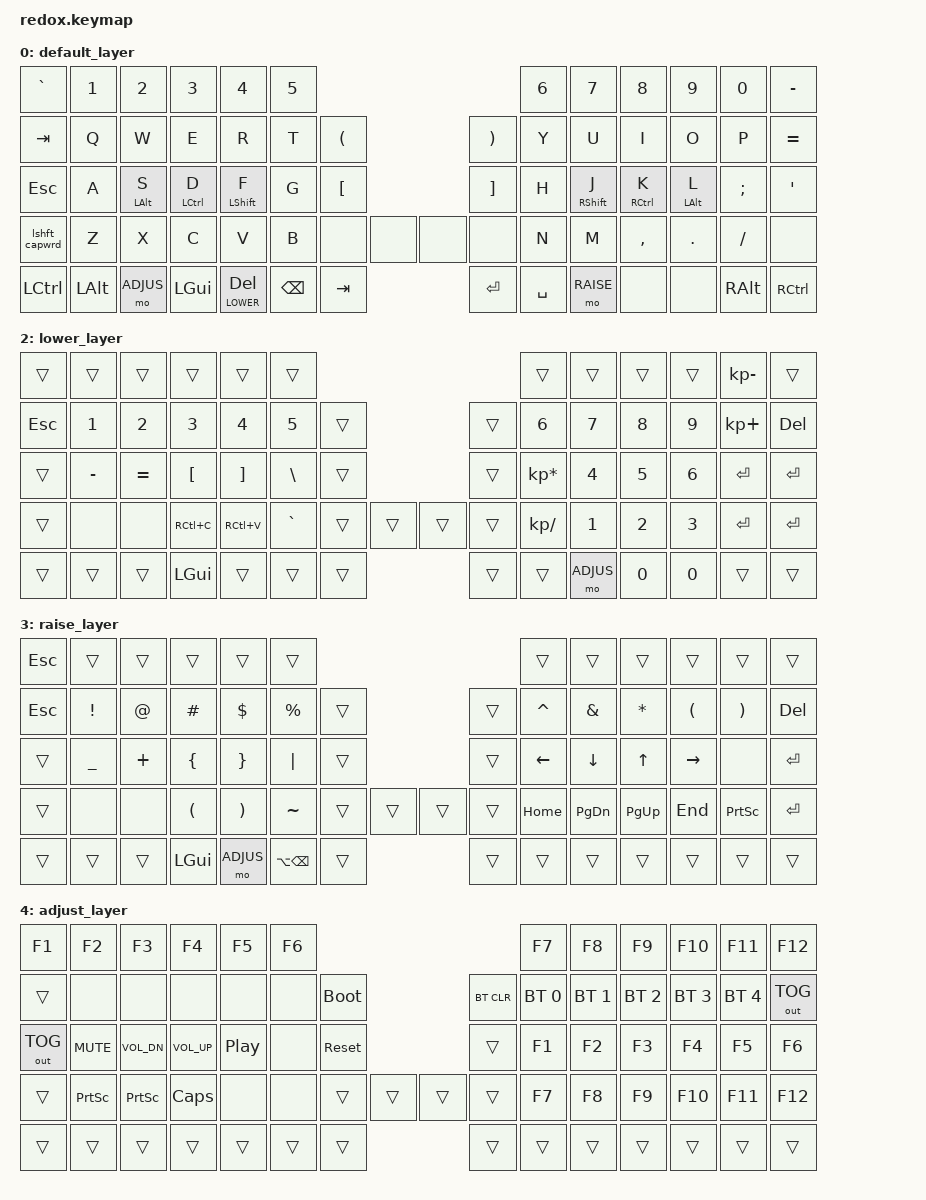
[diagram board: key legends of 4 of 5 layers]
/*
 * Copyright (c) 2021 The ZMK Contributors
 *
 * SPDX-License-Identifier: MIT
 */

#include <behaviors.dtsi>
#include <dt-bindings/zmk/keys.h>
#include <dt-bindings/zmk/bt.h>
#include <dt-bindings/zmk/ext_power.h>
#include <dt-bindings/zmk/outputs.h>

#include "zmk-helpers/key-labels/redox.h"
#include "zmk-helpers/helper.h"

#define NONE &none
#define ___ &trans

#define DEFAULT 0
#define GAME    1
#define LOWER   2
#define RAISE   3
#define ADJUS   4
#define EXTRA_1 5
#define EXTRA_2 6

/* Global settings */

#define QUICK_TAP_MS 175

&caps_word {
    continue-list = <UNDERSCORE MINUS BACKSPACE DELETE>;
};

&sk {  // sticky-key config
    release-after-ms = <900>;  // release after 0.9s
    quick-release;             // no double capitalization when rolling keys
};

&sl {  // sticky-layer config
    ignore-modifiers;          // allow chording sticky mods & layers
};

&lt {  // layer-tap config
    flavor = "balanced";
    tapping-term-ms = <200>;
    quick-tap-ms = <QUICK_TAP_MS>;
};

/* Homerow mods */

#define LN_ROW LN6 LN5 LN4 LN3 LN2 LN1
#define LT_ROW LT6 LT5 LT4 LT3 LT2 LT1 LT0
#define LM_ROW LM6 LM5 LM4 LM3 LM2 LM1 LM0
#define LB_ROW LB6 LB5 LB4 LB3 LB2 LB1
#define LF_ROW LF6 LF5 LF4 LF3
#define L_THUMB LH4 LH3 LH2 LH1 LH0

#define RN_ROW RN6 RN5 RN4 RN3 RN2 RN1
#define RT_ROW RT6 RT5 RT4 RT3 RT2 RT1 RT0
#define RM_ROW RM6 RM5 RM4 RM3 RM2 RM1 RM0
#define RB_ROW RB6 RB5 RB4 RB3 RB2 RB1
#define RF_ROW RF6 RF5 RF4 RF3
#define R_THUMB RH4 RH3 RH2 RH1 RH0

#define KEYS_L LN_ROW LT_ROW LM_ROW LB_ROW LF_ROW // left hand
#define KEYS_R RN_ROW RT_ROW RM_ROW RB_ROW RF_ROW // right hand

#define THUMBS L_THUMB R_THUMB

#define MAKE_HRM(NAME, HOLD, TAP, TRIGGER_POS) \
    ZMK_HOLD_TAP(NAME, \
        flavor = "balanced"; \
        tapping-term-ms = <200>; \
        quick-tap-ms = <QUICK_TAP_MS>; \
        require-prior-idle-ms = <150>; \
        bindings = <HOLD>, <TAP>; \
        hold-trigger-key-positions = <TRIGGER_POS>; \
        hold-trigger-on-release; \
    )
MAKE_HRM(hml, &kp, &kp, KEYS_R THUMBS)  // left-hand HRMs
MAKE_HRM(hmr, &kp, &kp, KEYS_L THUMBS)  // right-hand HRMs


ZMK_COMBO(toggle_game_layer, &tog GAME, LB2 LB1, DEFAULT GAME)


/ {
    behaviors {
        lshft_capwrd: behavior_lshift_capsword {
            compatible = "zmk,behavior-tap-dance";
            label = "LSHFT_CAPSWORD";
            #binding-cells = <0>;
            tapping-term-ms = <200>;
            bindings = <&kp LSHFT>, <&caps_word>;
        };
    };

    keymap {
        compatible =  "zmk,keymap" ;

        default_layer {
// --------------------------------------------------------------------------------------------------------------------------------
// | `     |  1  |  2  |   3   |  4  |  5  |                   ---                |  6    |  7    |  8    |  9   | 0    |     -     |
// | TAB   |  Q  |  W  |   E   |  R  |  T  |   (   |           ---        |  )    |  Y    |  U    |  I    |  O   | P    |     =     |
// | ESC   |  A  |  S  |   D   |  F  |  G  |   [   |           ---        |  ]    |  H    |  J    |  K    |  L   | ;    |     '     |
// | SHIFT |  Z  |  X  |   C   |  V  |  B  | NONE  | NONE    | --- | NONE | NONE  |  N    |  M    |  ,    |  .   | /    |   SHIFT   |
// | CRTL  | ALT |ADJUS| GUI   | LOWER/DEL | BSPC  | TAB     | --- | RET  | SPACE |     RAISE     | NONE  | NONE | RALT |   RCTRL   |
            bindings = <
// ╭───────────────┬───────────────┬───────────────┬───────────────┬───────────────┬───────────────╮                                                                  ╭───────────────┬───────────────┬───────────────┬───────────────┬───────────────┬───────────────╮
     &kp GRAVE       &kp N1          &kp N2          &kp N3          &kp N4          &kp N5                                                                             &kp N6          &kp N7          &kp N8          &kp N9          &kp N0          &kp MINUS
// ├───────────────┼───────────────┼───────────────┼───────────────┼───────────────┼───────────────┼───────────────╮                                  ╭───────────────┼───────────────┼───────────────┼───────────────┼───────────────┼───────────────┼───────────────┤
     &kp TAB         &kp Q           &kp W           &kp E           &kp R           &kp T           &kp LPAR                                           &kp RPAR        &kp Y           &kp U           &kp I           &kp O           &kp P           &kp EQUAL
// ├───────────────┼───────────────┼───────────────┼───────────────┼───────────────┼───────────────┼───────────────┤                                  ├───────────────┼───────────────┼───────────────┼───────────────┼───────────────┼───────────────┼───────────────┤
     &kp ESC         &kp A           &hml LALT S     &hml LCTRL D    &hml LSHFT F    &kp G           &kp LBKT                                           &kp RBKT        &kp H           &hmr RSHFT J    &hmr RCTRL K    &hmr LALT L     &kp SEMI        &kp SQT
// ├───────────────┼───────────────┼───────────────┼───────────────┼───────────────┼───────────────┼───────────────┼───────────────╮  ╭───────────────┼───────────────┼───────────────┼───────────────┼───────────────┼───────────────┼───────────────┼───────────────┤
     &lshft_capwrd   &kp Z           &kp X           &kp C           &kp V           &kp B           NONE            NONE               NONE            NONE            &kp N           &kp M           &kp COMMA       &kp DOT         &kp FSLH        NONE
// ├───────────────┼───────────────┼───────────────┼───────────────┼───────────────┼───────────────┼───────────────┼───────────────┤  ├───────────────┼───────────────┼───────────────┼───────────────┼───────────────┼───────────────┼───────────────┼───────────────┤
     &kp LCTRL       &kp LALT        &mo ADJUS       &kp LGUI                &lt LOWER DEL           &kp BSPC        &kp TAB            &kp RET         &kp SPACE                &mo RAISE              NONE            NONE            &kp RALT        &kp RCTRL
// ╰───────────────┴───────────────┴───────────────┴───────────────┴───────────────────────────────┴───────────────┴───────────────╯  ╰───────────────┴───────────────┴───────────────────────────────┴───────────────┴───────────────┴───────────────┴───────────────╯
            >;
        };

        game_layer {
// --------------------------------------------------------------------------------------------------------------------------------
// | `     |  1  |  2  |   3   |  4  |  5  |                   ---                |  6    |  7    |  8    |  9   | 0    |     -     |
// | TAB   |  Q  |  W  |   E   |  R  |  T  |   (   |           ---        |  )    |  Y    |  U    |  I    |  O   | P    |     =     |
// | ESC   |  A  |  S  |   D   |  F  |  G  |   [   |           ---        |  ]    |  H    |  J    |  K    |  L   | ;    |     '     |
// | SHIFT |  Z  |  X  |   C   |  V  |  B  | NONE  | NONE    | --- | NONE | NONE  |  N    |  M    |  ,    |  .   | /    |   SHIFT   |
// | CRTL  | ALT |ADJUS| GUI   | LOWER/DEL | BSPC  | TAB     | --- | RET  | SPACE |     RAISE     | NONE  | NONE | RALT |   RCTRL   |
            bindings = <
// ╭───────────────┬───────────────┬───────────────┬───────────────┬───────────────┬───────────────╮                                                                  ╭───────────────┬───────────────┬───────────────┬───────────────┬───────────────┬───────────────╮
     ___             ___             ___             ___             ___             ___                                                                                ___             ___             ___             ___             ___             ___
// ├───────────────┼───────────────┼───────────────┼───────────────┼───────────────┼───────────────┼───────────────╮                                  ╭───────────────┼───────────────┼───────────────┼───────────────┼───────────────┼───────────────┼───────────────┤
     ___             ___             ___             ___             ___             ___             ___                                                ___             ___             ___             ___             ___             ___             ___
// ├───────────────┼───────────────┼───────────────┼───────────────┼───────────────┼───────────────┼───────────────┤                                  ├───────────────┼───────────────┼───────────────┼───────────────┼───────────────┼───────────────┼───────────────┤
     ___             &kp A           &kp S           &kp D           &kp F           ___             ___                                                ___             ___             &kp J           &kp K           &kp L           &kp SEMI        ___
// ├───────────────┼───────────────┼───────────────┼───────────────┼───────────────┼───────────────┼───────────────┼───────────────╮  ╭───────────────┼───────────────┼───────────────┼───────────────┼───────────────┼───────────────┼───────────────┼───────────────┤
     ___             ___             ___             ___             ___             ___             ___             ___                ___             ___             ___             ___             ___             ___             ___             ___
// ├───────────────┼───────────────┼───────────────┼───────────────┼───────────────┼───────────────┼───────────────┼───────────────┤  ├───────────────┼───────────────┼───────────────┼───────────────┼───────────────┼───────────────┼───────────────┼───────────────┤
     ___             ___             ___             ___             ___             ___             ___             ___                ___             ___             ___             ___             ___             ___             ___             ___
// ╰───────────────┴───────────────┴───────────────┴───────────────┴───────────────────────────────┴───────────────┴───────────────╯  ╰───────────────┴───────────────┴───────────────────────────────┴───────────────┴───────────────┴───────────────┴───────────────╯
            >;
        };

        lower_layer {
// -------------------------------------------------------------------------------------------------------------------------------------
// | `     |  1  |  2  |   3   |   4   |  5    |                       ---                   |  6  |  7  |  8   |  9   |  -    |  -     |
// | ESC   |  1  |  2  |   3   |   4   |  5    |   (     |             ---           |  )    |  6  |  7  |  8   |  9   |  +    |  DEL   |
// | ESC   |  -  |  =  |   [   |   ]   |  \    |   [     |             ---           |  ]    |  *  |  4  |  5   |  6   |  RET  |  RET   |
// | SHIFT | NONE| NONE| COPY  | PASTE | GRAVE | DEL     | LALT    |   ---   | HOME  | END   |  \  |  1  |  2   |  3   |  RET  |  RET   |
// | CRTL  | ALT |ADJUS| GUI   |     LOWER     | BSPC    | LCTRL   |   ---   | RET   | SPACE |   RAISE   |  0   |  0   |  RALT |  RCTRL |
            bindings = <
// ╭───────────────┬───────────────┬───────────────┬───────────────┬───────────────┬───────────────╮                                                                  ╭───────────────┬───────────────┬───────────────┬───────────────┬───────────────┬───────────────╮
      ___             ___             ___             ___             ___             ___                                                                                ___             ___             ___             ___            &kp KP_MINUS     ___
// ├───────────────┼───────────────┼───────────────┼───────────────┼───────────────┼───────────────┼───────────────╮                                  ╭───────────────┼───────────────┼───────────────┼───────────────┼───────────────┼───────────────┼───────────────┤
     &kp ESC         &kp N1          &kp N2          &kp N3          &kp N4          &kp N5           ___                                                ___            &kp N6          &kp N7          &kp N8          &kp N9          &kp KP_PLUS     &kp DEL
// ├───────────────┼───────────────┼───────────────┼───────────────┼───────────────┼───────────────┼───────────────┤                                  ├───────────────┼───────────────┼───────────────┼───────────────┼───────────────┼───────────────┼───────────────┤
      ___            &kp MINUS       &kp EQUAL       &kp LBKT        &kp RBKT        &kp BSLH         ___                                                ___            &kp KP_MULTIPLY &kp N4          &kp N5          &kp N6          &kp RET         &kp RET
// ├───────────────┼───────────────┼───────────────┼───────────────┼───────────────┼───────────────┼───────────────┼───────────────╮  ╭───────────────┼───────────────┼───────────────┼───────────────┼───────────────┼───────────────┼───────────────┼───────────────┤
      ___            NONE            NONE            &kp RC(C)       &kp RC(V)       &kp GRAVE        ___             ___                ___             ___            &kp KP_DIVIDE   &kp N1          &kp N2          &kp N3          &kp RET         &kp RET
// ├───────────────┼───────────────┼───────────────┼───────────────┼───────────────┼───────────────┼───────────────┼───────────────┤  ├───────────────┼───────────────┼───────────────┼───────────────┼───────────────┼───────────────┼───────────────┼───────────────┤
      ___             ___             ___            &kp LGUI                     ___                 ___             ___                ___             ___                     &mo ADJUS              &kp N0          &kp N0           ___             ___
// ╰───────────────┴───────────────┴───────────────┴───────────────┴───────────────────────────────┴───────────────┴───────────────╯  ╰───────────────┴───────────────┴───────────────────────────────┴───────────────┴───────────────┴───────────────┴───────────────╯
            >;
        };

        raise_layer {
// ----------------------------------------------------------------------------------------------------------------------------
// | ESC   |  1  |  2  |   3   |  4  |  5  |                   ---                |  6   |  7   |  8   |  9   |  0    |  DEL  |
// | ESC   |  !  |  @  |   #   |  $  |  %  |   (   |           ---        |  )    |  ^   |  &   |  *   |  (   |  )    |  DEL  |
// | ESC   |  _  |  +  |   {   |  }  | "|" |   [   |           ---        |  ]    | LEFT | DOWN | UP   | RIGHT|       |  RET  |
// | SHIFT | NONE| NONE|   (   |  )  |  ~  | DEL   | LALT    | --- | HOME | END   | HOME | PGDN | PGUP | END  | PRCNT |  RET  |
// | CRTL  | ALT |ADJUS| GUI   |   LOWER   | BSPC  | LCTRL   | --- | RET  | SPACE |    RAISE    | NONE | NONE |  RALT |  RCTRL|
            bindings = <
// ╭───────────────┬───────────────┬───────────────┬───────────────┬───────────────┬───────────────╮                                                                  ╭───────────────┬───────────────┬───────────────┬───────────────┬───────────────┬───────────────╮
     &kp ESC          ___             ___             ___             ___             ___                                                                                ___             ___             ___             ___             ___             ___
// ├───────────────┼───────────────┼───────────────┼───────────────┼───────────────┼───────────────┼───────────────╮                                  ╭───────────────┼───────────────┼───────────────┼───────────────┼───────────────┼───────────────┼───────────────┤
     &kp ESC         &kp EXCL        &kp AT          &kp HASH        &kp DLLR        &kp PRCNT        ___                                                ___            &kp CARET       &kp AMPS        &kp ASTRK       &kp LPAR        &kp RPAR        &kp DEL
// ├───────────────┼───────────────┼───────────────┼───────────────┼───────────────┼───────────────┼───────────────┤                                  ├───────────────┼───────────────┼───────────────┼───────────────┼───────────────┼───────────────┼───────────────┤
      ___            &kp UNDER       &kp PLUS        &kp LBRC        &kp RBRC        &kp PIPE         ___                                                ___            &kp LEFT        &kp DOWN        &kp UP          &kp RIGHT       NONE            &kp RET
// ├───────────────┼───────────────┼───────────────┼───────────────┼───────────────┼───────────────┼───────────────┼───────────────╮  ╭───────────────┼───────────────┼───────────────┼───────────────┼───────────────┼───────────────┼───────────────┼───────────────┤
      ___            NONE            NONE            &kp LPAR        &kp RPAR        &kp TILDE        ___             ___                ___             ___            &kp HOME        &kp PG_DN       &kp PG_UP       &kp END         &kp PSCRN       &kp RET
// ├───────────────┼───────────────┼───────────────┼───────────────┼───────────────┼───────────────┼───────────────┼───────────────┤  ├───────────────┼───────────────┼───────────────┼───────────────┼───────────────┼───────────────┼───────────────┼───────────────┤
      ___             ___             ___            &kp LGUI                  &mo ADJUS             &kp LA(BSPC)     ___                ___             ___                        ___                  ___             ___             ___             ___
// ╰───────────────┴───────────────┴───────────────┴───────────────┴───────────────────────────────┴───────────────┴───────────────╯  ╰───────────────┴───────────────┴───────────────────────────────┴───────────────┴───────────────┴───────────────┴───────────────╯
            >;
        };

        adjust_layer {
// -----------------------------------------------------------------------------------------
// |  F1   |  F2   |    F3    |    F4     |     F5     | F6 |                   ---                | F7  | F8  |  F9  |  F10 | F11 | F12        |
// | TAB   |       |          |           |            |    | BOOTL |           ---        | BTCLR | BT1 | BT2 |  BT3 |  BT4 | BT5 | OUTPUT TGL |
// | CTRL  | MUTE  |  Vol Dn  |  Vol Up   | Play/Pause |    | RESET |           ---        |  ]    | F1  | F2  |  F3  |  F4  | F5  | F6         |
// | SHIFT | PSCRN |  PSCRN   |   CAPS    |            |    | DEL   | LALT    | --- | HOME | END   | F7  | F8  |  F9  |  F10 | F11 | F12        |
// | CRTL  | ALT   |  ADJUS   |   GUI     |        LOWER    | BSPC  | LCTRL   | --- | RET  | SPACE |   RAISE   | LEFT | DOWN | UP  |   RIGHT    |
            bindings = <
// ╭───────────────┬───────────────┬───────────────┬───────────────┬───────────────┬───────────────╮                                                                  ╭───────────────┬───────────────┬───────────────┬───────────────┬───────────────┬───────────────╮
     &kp F1          &kp F2          &kp F3          &kp F4          &kp F5           &kp F6                                                                            &kp F7          &kp F8          &kp F9          &kp F10         &kp F11         &kp F12
// ├───────────────┼───────────────┼───────────────┼───────────────┼───────────────┼───────────────┼───────────────╮                                  ╭───────────────┼───────────────┼───────────────┼───────────────┼───────────────┼───────────────┼───────────────┤
      ___            NONE            NONE            NONE            NONE             NONE           &bootloader                                        &bt BT_CLR      &bt BT_SEL 0    &bt BT_SEL 1    &bt BT_SEL 2    &bt BT_SEL 3    &bt BT_SEL 4    &out OUT_TOG
// ├───────────────┼───────────────┼───────────────┼───────────────┼───────────────┼───────────────┼───────────────┤                                  ├───────────────┼───────────────┼───────────────┼───────────────┼───────────────┼───────────────┼───────────────┤
      &out OUT_TOG   &kp K_MUTE      &kp C_VOL_DN    &kp C_VOL_UP    &kp C_PLAY_PAUSE NONE           &sys_reset                                          ___            &kp F1          &kp F2          &kp F3          &kp F4          &kp F5          &kp F6
// ├───────────────┼───────────────┼───────────────┼───────────────┼───────────────┼───────────────┼───────────────┼───────────────╮  ╭───────────────┼───────────────┼───────────────┼───────────────┼───────────────┼───────────────┼───────────────┼───────────────┤
      ___            &kp PSCRN       &kp PSCRN       &kp CLCK        NONE             NONE            ___             ___                ___             ___            &kp F7          &kp F8          &kp F9          &kp F10         &kp F11         &kp F12
// ├───────────────┼───────────────┼───────────────┼───────────────┼───────────────┼───────────────┼───────────────┼───────────────┤  ├───────────────┼───────────────┼───────────────┼───────────────┼───────────────┼───────────────┼───────────────┼───────────────┤
      ___             ___             ___             ___                        ___                  ___             ___                ___             ___                         ___                 ___             ___             ___             ___
// ╰───────────────┴───────────────┴───────────────┴───────────────┴───────────────────────────────┴───────────────┴───────────────╯  ╰───────────────┴───────────────┴───────────────────────────────┴───────────────┴───────────────┴───────────────┴───────────────╯
            >;
        };

        extra1 {
            status = "reserved";
        };

        extra2 {
            status = "reserved";
        };
    };
};
